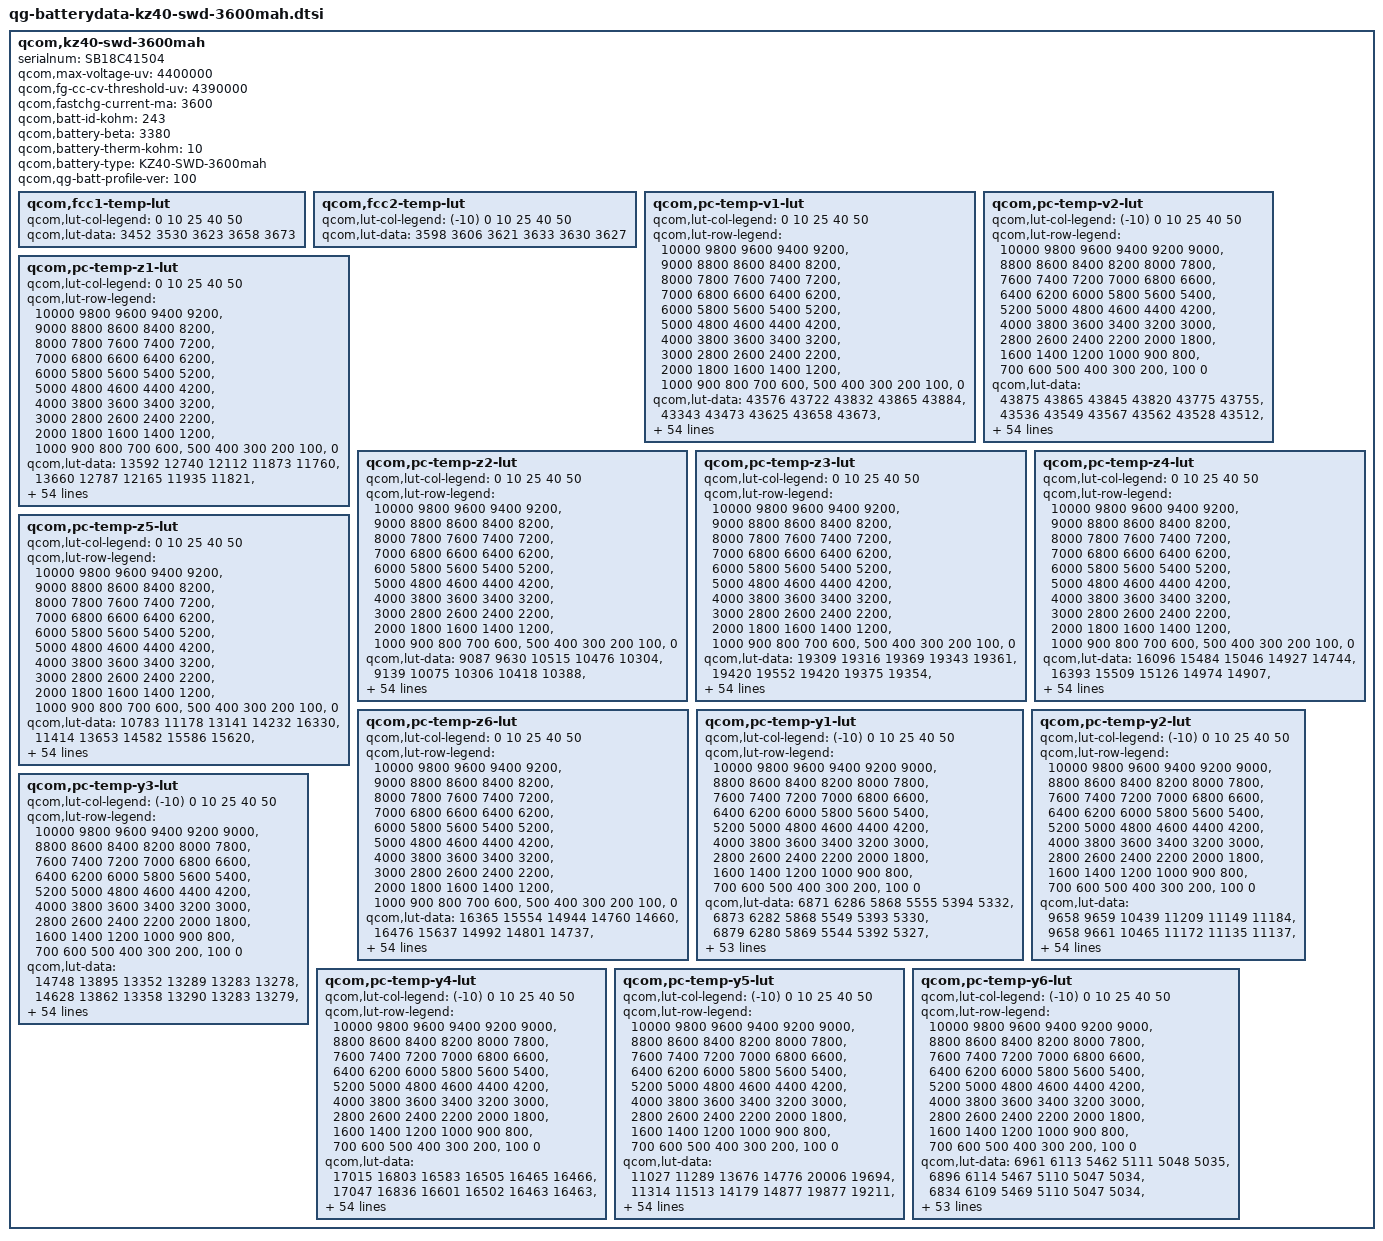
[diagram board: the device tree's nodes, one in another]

qcom,kz40-swd-3600mah {
    /* 3773938_Lenovo_KZ40_3600mAh_averaged_MasterSlave_Nov29th2018 */
    serialnum = "SB18C41504";
    qcom,max-voltage-uv = <4400000>;
    qcom,fg-cc-cv-threshold-uv = <4390000>;
    qcom,fastchg-current-ma = <3600>;
    qcom,batt-id-kohm = <243>;
    qcom,battery-beta = <3380>;
    qcom,battery-therm-kohm = <10>;
    qcom,battery-type = "KZ40-SWD-3600mah";
    qcom,qg-batt-profile-ver = <100>;

	qcom,fcc1-temp-lut {
		qcom,lut-col-legend = <0 10 25 40 50>;
		qcom,lut-data = <3452 3530 3623 3658 3673>;
	};

	qcom,fcc2-temp-lut {
		qcom,lut-col-legend = <(-10) 0 10 25 40 50>;
		qcom,lut-data = <3598 3606 3621 3633 3630 3627>;
	};

	qcom,pc-temp-v1-lut {
		qcom,lut-col-legend = <0 10 25 40 50>;
		qcom,lut-row-legend = <10000 9800 9600 9400 9200>,
			<9000 8800 8600 8400 8200>,
			<8000 7800 7600 7400 7200>,
			<7000 6800 6600 6400 6200>,
			<6000 5800 5600 5400 5200>,
			<5000 4800 4600 4400 4200>,
			<4000 3800 3600 3400 3200>,
			<3000 2800 2600 2400 2200>,
			<2000 1800 1600 1400 1200>,
			<1000 900 800 700 600>,
			<500 400 300 200 100>,
			<0>;
		qcom,lut-data = <43576 43722 43832 43865 43884>,
			<43343 43473 43625 43658 43673>,
			<43080 43230 43397 43442 43461>,
			<42820 42994 43164 43221 43244>,
			<42585 42761 42928 42992 43021>,
			<42361 42527 42689 42757 42788>,
			<42144 42296 42456 42523 42555>,
			<41931 42073 42224 42289 42322>,
			<41725 41857 41995 42058 42090>,
			<41527 41648 41768 41829 41861>,
			<41337 41445 41545 41602 41635>,
			<41143 41250 41329 41380 41413>,
			<40940 41052 41119 41159 41192>,
			<40730 40857 40915 40946 40976>,
			<40498 40655 40715 40741 40768>,
			<40226 40424 40518 40545 40566>,
			<39990 40165 40315 40354 40373>,
			<39835 39960 40112 40170 40189>,
			<39712 39828 39934 39993 40011>,
			<39588 39714 39794 39832 39846>,
			<39458 39581 39644 39671 39685>,
			<39330 39433 39414 39464 39490>,
			<39205 39268 39126 39185 39229>,
			<39083 39050 38922 38960 38999>,
			<38965 38821 38793 38828 38855>,
			<38851 38669 38688 38723 38740>,
			<38742 38562 38596 38618 38627>,
			<38641 38480 38516 38515 38518>,
			<38546 38416 38438 38421 38419>,
			<38463 38365 38361 38335 38329>,
			<38394 38320 38291 38259 38247>,
			<38335 38278 38228 38189 38173>,
			<38293 38240 38173 38128 38106>,
			<38267 38207 38123 38069 38043>,
			<38244 38178 38079 38017 37986>,
			<38210 38144 38037 37966 37930>,
			<38168 38110 37995 37916 37869>,
			<38117 38068 37953 37867 37807>,
			<38057 38004 37893 37803 37733>,
			<37983 37912 37802 37711 37640>,
			<37891 37809 37695 37603 37533>,
			<37766 37690 37578 37483 37413>,
			<37626 37556 37444 37347 37277>,
			<37469 37403 37282 37187 37118>,
			<37324 37261 37145 37053 36988>,
			<37225 37170 37061 36975 36918>,
			<37191 37138 37039 36956 36896>,
			<37166 37114 37027 36941 36881>,
			<37142 37090 37007 36921 36862>,
			<37084 37036 36947 36845 36768>,
			<36838 36773 36670 36543 36449>,
			<36382 36319 36224 36089 35991>,
			<35798 35734 35641 35499 35399>,
			<35004 34932 34841 34688 34585>,
			<33739 33667 33590 33417 33304>,
			<30000 30000 30000 30000 30000>;
	};

	qcom,pc-temp-v2-lut {
		qcom,lut-col-legend = <(-10) 0 10 25 40 50>;
		qcom,lut-row-legend = <10000 9800 9600 9400 9200 9000>,
			<8800 8600 8400 8200 8000 7800>,
			<7600 7400 7200 7000 6800 6600>,
			<6400 6200 6000 5800 5600 5400>,
			<5200 5000 4800 4600 4400 4200>,
			<4000 3800 3600 3400 3200 3000>,
			<2800 2600 2400 2200 2000 1800>,
			<1600 1400 1200 1000 900 800>,
			<700 600 500 400 300 200>,
			<100 0>;
		qcom,lut-data = <43875 43865 43845 43820 43775 43755>,
			<43536 43549 43567 43562 43528 43512>,
			<43215 43247 43300 43310 43285 43273>,
			<42910 42961 43044 43067 43046 43037>,
			<42621 42689 42798 42833 42813 42805>,
			<42349 42427 42557 42600 42580 42573>,
			<42095 42173 42315 42367 42347 42340>,
			<41854 41927 42076 42135 42114 42108>,
			<41614 41686 41845 41906 41885 41880>,
			<41368 41446 41620 41680 41658 41655>,
			<41165 41232 41400 41455 41434 41432>,
			<41038 41067 41184 41231 41214 41213>,
			<40925 40912 40974 41014 40998 40997>,
			<40694 40711 40783 40818 40790 40788>,
			<40230 40456 40608 40640 40586 40584>,
			<39830 40188 40411 40446 40390 40387>,
			<39619 39906 40155 40207 40199 40199>,
			<39455 39629 39885 39971 40015 40018>,
			<39287 39410 39666 39802 39842 39845>,
			<39120 39231 39478 39670 39679 39681>,
			<38962 39064 39293 39506 39494 39496>,
			<38808 38896 39096 39257 39253 39255>,
			<38663 38738 38908 39002 39012 39012>,
			<38538 38595 38746 38821 38832 38832>,
			<38426 38462 38602 38673 38681 38683>,
			<38329 38349 38475 38546 38553 38554>,
			<38246 38257 38364 38434 38442 38443>,
			<38172 38178 38264 38335 38342 38344>,
			<38104 38110 38171 38243 38250 38250>,
			<38040 38050 38082 38159 38164 38162>,
			<37982 37997 38009 38082 38086 38084>,
			<37927 37947 37947 38008 38017 38014>,
			<37875 37900 37894 37939 37951 37947>,
			<37820 37854 37841 37878 37884 37876>,
			<37764 37809 37791 37821 37816 37800>,
			<37705 37762 37742 37760 37737 37712>,
			<37644 37711 37695 37695 37641 37600>,
			<37581 37655 37645 37625 37541 37488>,
			<37514 37591 37584 37550 37457 37397>,
			<37445 37520 37513 37470 37378 37316>,
			<37375 37438 37429 37383 37290 37227>,
			<37305 37335 37322 37285 37191 37126>,
			<37232 37222 37204 37165 37074 37008>,
			<37156 37103 37079 37022 36935 36868>,
			<37073 36996 36964 36913 36838 36781>,
			<36972 36910 36887 36875 36812 36757>,
			<36912 36872 36854 36864 36798 36747>,
			<36852 36826 36814 36842 36779 36730>,
			<36766 36767 36760 36805 36741 36683>,
			<36637 36662 36647 36683 36574 36487>,
			<36408 36426 36369 36317 36188 36090>,
			<36027 35969 35888 35801 35652 35551>,
			<35446 35322 35226 35112 34949 34837>,
			<34590 34390 34272 34142 33948 33847>,
			<33143 32941 32907 32689 32621 32440>,
			<30208 27623 27450 28102 27502 27416>;
	};

	qcom,pc-temp-z1-lut {
		qcom,lut-col-legend = <0 10 25 40 50>;
		qcom,lut-row-legend = <10000 9800 9600 9400 9200>,
			<9000 8800 8600 8400 8200>,
			<8000 7800 7600 7400 7200>,
			<7000 6800 6600 6400 6200>,
			<6000 5800 5600 5400 5200>,
			<5000 4800 4600 4400 4200>,
			<4000 3800 3600 3400 3200>,
			<3000 2800 2600 2400 2200>,
			<2000 1800 1600 1400 1200>,
			<1000 900 800 700 600>,
			<500 400 300 200 100>,
			<0>;
		qcom,lut-data = <13592 12740 12112 11873 11760>,
			<13660 12787 12165 11935 11821>,
			<13669 12808 12188 11936 11824>,
			<13675 12818 12195 11936 11825>,
			<13672 12821 12187 11932 11824>,
			<13659 12811 12176 11923 11818>,
			<13653 12793 12171 11917 11815>,
			<13655 12782 12168 11913 11816>,
			<13656 12776 12166 11910 11817>,
			<13648 12773 12166 11908 11816>,
			<13623 12778 12166 11906 11815>,
			<13601 12792 12170 11905 11814>,
			<13560 12798 12177 11905 11814>,
			<13503 12780 12179 11905 11815>,
			<13469 12756 12167 11905 11815>,
			<13443 12741 12154 11904 11816>,
			<13423 12726 12152 11905 11817>,
			<13407 12720 12152 11907 11820>,
			<13391 12733 12155 11911 11822>,
			<13389 12752 12165 11913 11825>,
			<13408 12763 12176 11915 11827>,
			<13433 12769 12178 11917 11828>,
			<13446 12775 12179 11919 11829>,
			<13458 12782 12180 11921 11831>,
			<13465 12790 12179 11924 11834>,
			<13469 12792 12179 11928 11838>,
			<13472 12786 12183 11932 11843>,
			<13472 12782 12190 11937 11848>,
			<13469 12790 12196 11942 11853>,
			<13468 12805 12200 11947 11857>,
			<13477 12812 12203 11953 11861>,
			<13494 12818 12206 11958 11866>,
			<13508 12824 12208 11962 11871>,
			<13516 12825 12211 11966 11877>,
			<13523 12823 12223 11971 11883>,
			<13531 12826 12232 11977 11888>,
			<13541 12840 12234 11981 11893>,
			<13550 12855 12235 11986 11898>,
			<13556 12866 12238 11990 11902>,
			<13562 12876 12246 11995 11907>,
			<13576 12881 12255 12001 11912>,
			<13612 12883 12261 12006 11917>,
			<13631 12886 12265 12012 11921>,
			<13636 12893 12265 12018 11925>,
			<13650 12915 12271 12024 11929>,
			<13664 12898 12274 12027 11932>,
			<13646 12903 12277 12027 11935>,
			<13656 12916 12270 12028 11936>,
			<13640 12909 12282 12035 11939>,
			<13671 12904 12284 12039 11945>,
			<13661 12913 12287 12046 11953>,
			<13716 12950 12301 12055 11963>,
			<13745 12982 12320 12068 11977>,
			<13767 13040 12353 12086 11993>,
			<13767 13040 12353 12086 11993>,
			<13767 13040 12353 12086 11993>;
	};

	qcom,pc-temp-z2-lut {
		qcom,lut-col-legend = <0 10 25 40 50>;
		qcom,lut-row-legend = <10000 9800 9600 9400 9200>,
			<9000 8800 8600 8400 8200>,
			<8000 7800 7600 7400 7200>,
			<7000 6800 6600 6400 6200>,
			<6000 5800 5600 5400 5200>,
			<5000 4800 4600 4400 4200>,
			<4000 3800 3600 3400 3200>,
			<3000 2800 2600 2400 2200>,
			<2000 1800 1600 1400 1200>,
			<1000 900 800 700 600>,
			<500 400 300 200 100>,
			<0>;
		qcom,lut-data = <9087 9630 10515 10476 10304>,
			<9139 10075 10306 10418 10388>,
			<9625 10181 10387 10465 10427>,
			<10015 10160 10425 10501 10471>,
			<10065 10132 10394 10491 10470>,
			<10090 10106 10348 10447 10426>,
			<10101 10079 10314 10406 10386>,
			<10107 10059 10281 10360 10366>,
			<10111 10042 10270 10328 10347>,
			<10110 10031 10271 10329 10304>,
			<10105 10028 10274 10338 10220>,
			<10098 10027 10279 10347 10185>,
			<10079 10027 10289 10364 10201>,
			<10050 10051 10303 10375 10222>,
			<10018 10079 10325 10339 10234>,
			<9975 10085 10344 10266 10245>,
			<9949 10087 10345 10249 10250>,
			<9960 10091 10343 10268 10256>,
			<9984 10129 10344 10285 10266>,
			<9993 10176 10359 10294 10283>,
			<9980 10181 10372 10303 10306>,
			<9962 10170 10365 10300 10311>,
			<9951 10160 10340 10276 10298>,
			<9942 10154 10313 10261 10289>,
			<9938 10150 10278 10279 10320>,
			<9939 10150 10255 10321 10380>,
			<9941 10154 10282 10383 10403>,
			<9945 10159 10346 10491 10413>,
			<9951 10160 10373 10539 10417>,
			<9959 10161 10380 10455 10335>,
			<9972 10163 10383 10347 10212>,
			<9987 10167 10375 10320 10176>,
			<9984 10171 10359 10309 10161>,
			<9809 10176 10355 10307 10157>,
			<9613 10184 10363 10331 10188>,
			<9605 10193 10375 10365 10240>,
			<9674 10205 10394 10387 10294>,
			<9756 10217 10422 10406 10354>,
			<9860 10227 10448 10434 10383>,
			<9961 10235 10475 10490 10393>,
			<9971 10238 10493 10539 10399>,
			<9882 10197 10500 10553 10404>,
			<9806 10168 10505 10559 10408>,
			<9755 10102 10510 10562 10425>,
			<9659 10785 10550 10544 10429>,
			<9620 13816 10593 10471 10426>,
			<9615 12140 10576 10504 10423>,
			<9613 11889 10602 10493 10437>,
			<9600 12772 10603 10515 10514>,
			<9558 12818 10650 10633 10521>,
			<9456 12360 10815 10505 10290>,
			<9414 10860 10770 10392 10221>,
			<9363 10317 10762 10345 10172>,
			<9300 10057 10613 10265 10102>,
			<9300 10057 10613 10265 10102>,
			<9300 10057 10613 10265 10102>;
	};

	qcom,pc-temp-z3-lut {
		qcom,lut-col-legend = <0 10 25 40 50>;
		qcom,lut-row-legend = <10000 9800 9600 9400 9200>,
			<9000 8800 8600 8400 8200>,
			<8000 7800 7600 7400 7200>,
			<7000 6800 6600 6400 6200>,
			<6000 5800 5600 5400 5200>,
			<5000 4800 4600 4400 4200>,
			<4000 3800 3600 3400 3200>,
			<3000 2800 2600 2400 2200>,
			<2000 1800 1600 1400 1200>,
			<1000 900 800 700 600>,
			<500 400 300 200 100>,
			<0>;
		qcom,lut-data = <19309 19316 19369 19343 19361>,
			<19420 19552 19420 19375 19354>,
			<19699 19638 19458 19396 19372>,
			<19889 19663 19480 19409 19385>,
			<19879 19677 19492 19417 19395>,
			<19845 19685 19499 19423 19404>,
			<19814 19690 19498 19425 19408>,
			<19783 19691 19493 19424 19407>,
			<19757 19679 19488 19423 19405>,
			<19746 19666 19483 19418 19400>,
			<19738 19662 19478 19408 19389>,
			<19734 19660 19475 19401 19381>,
			<19732 19655 19473 19399 19379>,
			<19732 19622 19469 19396 19377>,
			<19744 19589 19455 19389 19374>,
			<19800 19588 19441 19379 19369>,
			<19844 19597 19439 19374 19365>,
			<19827 19602 19438 19372 19360>,
			<19786 19574 19437 19371 19356>,
			<19771 19539 19432 19369 19353>,
			<19779 19537 19428 19367 19351>,
			<19788 19553 19433 19368 19348>,
			<19791 19573 19446 19371 19346>,
			<19793 19594 19450 19374 19344>,
			<19795 19613 19439 19364 19341>,
			<19799 19617 19428 19350 19337>,
			<19803 19617 19424 19356 19343>,
			<19804 19617 19422 19388 19383>,
			<19804 19614 19423 19408 19408>,
			<19803 19608 19437 19412 19404>,
			<19799 19602 19451 19414 19397>,
			<19787 19595 19455 19412 19390>,
			<19756 19586 19458 19404 19384>,
			<19537 19577 19458 19397 19377>,
			<19300 19566 19453 19391 19368>,
			<19269 19559 19447 19385 19361>,
			<19267 19553 19443 19380 19358>,
			<19266 19548 19439 19375 19357>,
			<19264 19547 19434 19372 19356>,
			<19263 19548 19430 19370 19355>,
			<19262 19543 19427 19369 19355>,
			<19263 19459 19423 19370 19357>,
			<19264 19398 19419 19372 19360>,
			<19264 19287 19416 19372 19363>,
			<19265 19260 19405 19368 19361>,
			<19266 19257 19395 19357 19340>,
			<19266 19258 19393 19348 19339>,
			<19266 19258 19361 19346 19335>,
			<19266 19258 19358 19344 19323>,
			<19267 19257 19350 19337 19332>,
			<19270 19258 19335 19354 19360>,
			<19272 19259 19340 19367 19366>,
			<19275 19261 19332 19369 19366>,
			<19279 19262 19340 19372 19369>,
			<19279 19262 19340 19372 19369>,
			<19279 19262 19340 19372 19369>;
	};

	qcom,pc-temp-z4-lut {
		qcom,lut-col-legend = <0 10 25 40 50>;
		qcom,lut-row-legend = <10000 9800 9600 9400 9200>,
			<9000 8800 8600 8400 8200>,
			<8000 7800 7600 7400 7200>,
			<7000 6800 6600 6400 6200>,
			<6000 5800 5600 5400 5200>,
			<5000 4800 4600 4400 4200>,
			<4000 3800 3600 3400 3200>,
			<3000 2800 2600 2400 2200>,
			<2000 1800 1600 1400 1200>,
			<1000 900 800 700 600>,
			<500 400 300 200 100>,
			<0>;
		qcom,lut-data = <16096 15484 15046 14927 14744>,
			<16393 15509 15126 14974 14907>,
			<16209 15494 15080 14951 14897>,
			<16001 15355 15027 14913 14872>,
			<15859 15195 14966 14879 14847>,
			<15732 15099 14905 14844 14820>,
			<15628 15020 14863 14814 14793>,
			<15545 14961 14830 14787 14766>,
			<15472 14918 14801 14766 14745>,
			<15404 14882 14774 14753 14739>,
			<15342 14848 14753 14744 14738>,
			<15282 14816 14742 14735 14735>,
			<15222 14797 14735 14725 14727>,
			<15163 14786 14728 14717 14717>,
			<15098 14779 14719 14713 14709>,
			<15021 14772 14711 14709 14702>,
			<14961 14765 14707 14704 14696>,
			<14932 14763 14703 14695 14690>,
			<14913 14764 14699 14688 14685>,
			<14892 14767 14689 14683 14682>,
			<14865 14762 14681 14680 14680>,
			<14841 14739 14721 14698 14690>,
			<14828 14724 14821 14798 14780>,
			<14819 14766 14861 14860 14850>,
			<14811 14830 14867 14859 14848>,
			<14804 14844 14870 14858 14841>,
			<14798 14841 14862 14844 14821>,
			<14795 14836 14837 14792 14761>,
			<14794 14822 14811 14748 14716>,
			<14793 14799 14779 14725 14705>,
			<14791 14781 14751 14708 14698>,
			<14790 14766 14730 14698 14691>,
			<14800 14753 14713 14690 14683>,
			<15019 14743 14704 14688 14681>,
			<15264 14734 14699 14688 14682>,
			<15290 14727 14696 14689 14684>,
			<15274 14719 14694 14690 14686>,
			<15256 14714 14693 14690 14688>,
			<15242 14712 14694 14693 14691>,
			<15228 14711 14705 14702 14698>,
			<15217 14714 14714 14709 14703>,
			<15210 14802 14709 14705 14699>,
			<15199 14861 14704 14696 14691>,
			<15179 14974 14707 14699 14695>,
			<15072 14956 14699 14696 14691>,
			<15049 14922 14674 14677 14677>,
			<15045 14916 14663 14669 14665>,
			<15039 14910 14682 14651 14647>,
			<15032 14902 14674 14636 14639>,
			<15018 14898 14686 14650 14638>,
			<15017 14909 14730 14667 14650>,
			<15041 14921 14733 14661 14651>,
			<15058 14930 14746 14662 14655>,
			<15084 14945 14744 14664 14656>,
			<15084 14945 14744 14664 14656>,
			<15084 14945 14744 14664 14656>;
	};

	qcom,pc-temp-z5-lut {
		qcom,lut-col-legend = <0 10 25 40 50>;
		qcom,lut-row-legend = <10000 9800 9600 9400 9200>,
			<9000 8800 8600 8400 8200>,
			<8000 7800 7600 7400 7200>,
			<7000 6800 6600 6400 6200>,
			<6000 5800 5600 5400 5200>,
			<5000 4800 4600 4400 4200>,
			<4000 3800 3600 3400 3200>,
			<3000 2800 2600 2400 2200>,
			<2000 1800 1600 1400 1200>,
			<1000 900 800 700 600>,
			<500 400 300 200 100>,
			<0>;
		qcom,lut-data = <10783 11178 13141 14232 16330>,
			<11414 13653 14582 15586 15620>,
			<12696 14856 15676 16442 16548>,
			<13536 15370 16568 17038 17277>,
			<13528 15805 17356 17563 17988>,
			<13478 16467 17975 18023 18655>,
			<13441 17168 18322 18490 19334>,
			<13408 17512 18543 19066 20255>,
			<13385 17618 18892 19476 21017>,
			<13410 17734 19718 19537 20803>,
			<13504 18404 20771 19561 19717>,
			<13576 19782 21857 19681 19226>,
			<13581 20300 23019 20430 19791>,
			<13581 19322 23372 21046 20561>,
			<13962 18231 22701 20684 21032>,
			<15989 18977 22017 19938 21477>,
			<17577 21831 22326 19854 21627>,
			<17319 23253 23429 20753 21985>,
			<16674 20898 24453 21915 22505>,
			<16476 17830 25449 23153 23219>,
			<17189 17956 26772 24387 24161>,
			<18276 21353 31110 24929 24218>,
			<19165 26244 38942 25157 22385>,
			<20034 36237 40876 24998 20005>,
			<21113 47491 32753 21338 17450>,
			<22748 49192 24107 16413 15002>,
			<24723 45553 21195 16066 15163>,
			<26599 41334 19354 17877 18813>,
			<28712 38134 19070 19990 22092>,
			<29989 35157 20634 22187 23474>,
			<29639 32880 23022 24502 24570>,
			<28340 31179 25970 26594 26138>,
			<26188 29635 29654 28578 28175>,
			<18925 27827 32609 30192 29030>,
			<11699 26020 35323 31788 28964>,
			<10843 25107 36838 32833 28868>,
			<10835 24998 36861 32314 28803>,
			<10831 25275 36671 30433 28661>,
			<10827 26221 36006 28403 28298>,
			<10824 28073 32928 25583 25745>,
			<10826 28635 29678 23624 23342>,
			<10847 23041 27859 23759 23624>,
			<10870 18664 26365 24075 24324>,
			<10894 12421 24692 23476 24004>,
			<11108 11308 24350 22229 23025>,
			<11119 11255 24789 21494 18954>,
			<11096 11233 25058 20063 19563>,
			<11080 11206 17373 21777 21393>,
			<11066 11213 17226 24579 20459>,
			<11120 11252 16405 19724 22731>,
			<11204 11345 14182 18581 23306>,
			<11151 11289 14002 20086 23312>,
			<11085 11230 13330 19686 21422>,
			<10979 11150 13465 19233 20372>,
			<10979 11150 13465 19233 20372>,
			<10979 11150 13465 19233 20372>;
	};

	qcom,pc-temp-z6-lut {
		qcom,lut-col-legend = <0 10 25 40 50>;
		qcom,lut-row-legend = <10000 9800 9600 9400 9200>,
			<9000 8800 8600 8400 8200>,
			<8000 7800 7600 7400 7200>,
			<7000 6800 6600 6400 6200>,
			<6000 5800 5600 5400 5200>,
			<5000 4800 4600 4400 4200>,
			<4000 3800 3600 3400 3200>,
			<3000 2800 2600 2400 2200>,
			<2000 1800 1600 1400 1200>,
			<1000 900 800 700 600>,
			<500 400 300 200 100>,
			<0>;
		qcom,lut-data = <16365 15554 14944 14760 14660>,
			<16476 15637 14992 14801 14737>,
			<16446 15642 14985 14798 14737>,
			<16397 15558 14974 14791 14737>,
			<16310 15460 14949 14782 14735>,
			<16178 15396 14916 14768 14726>,
			<16070 15341 14891 14754 14716>,
			<15986 15294 14869 14742 14706>,
			<15914 15253 14851 14731 14695>,
			<15856 15218 14833 14721 14688>,
			<15807 15191 14820 14711 14681>,
			<15757 15169 14814 14704 14675>,
			<15695 15144 14811 14698 14670>,
			<15636 15108 14805 14693 14665>,
			<15597 15078 14788 14686 14660>,
			<15572 15072 14773 14679 14655>,
			<15549 15071 14771 14674 14649>,
			<15518 15068 14770 14669 14644>,
			<15486 15059 14768 14666 14640>,
			<15474 15049 14763 14663 14637>,
			<15472 15048 14759 14661 14635>,
			<15471 15052 14780 14669 14639>,
			<15472 15058 14832 14715 14677>,
			<15474 15088 14849 14743 14706>,
			<15476 15129 14848 14740 14705>,
			<15478 15138 14846 14734 14701>,
			<15481 15139 14840 14729 14697>,
			<15484 15140 14831 14724 14693>,
			<15487 15135 14824 14720 14689>,
			<15490 15125 14820 14714 14683>,
			<15488 15117 14816 14708 14677>,
			<15485 15110 14812 14703 14671>,
			<15480 15104 14808 14697 14665>,
			<15469 15098 14805 14693 14661>,
			<15460 15093 14803 14690 14657>,
			<15458 15091 14801 14689 14654>,
			<15458 15091 14800 14687 14654>,
			<15458 15091 14800 14686 14655>,
			<15461 15094 14801 14686 14656>,
			<15465 15102 14806 14690 14659>,
			<15471 15107 14811 14694 14662>,
			<15479 15110 14810 14693 14662>,
			<15486 15112 14808 14692 14661>,
			<15493 15116 14811 14695 14664>,
			<15470 15108 14807 14692 14663>,
			<15464 15099 14795 14680 14648>,
			<15463 15098 14790 14672 14641>,
			<15461 15097 14783 14664 14632>,
			<15461 15097 14780 14657 14622>,
			<15466 15101 14784 14661 14627>,
			<15477 15114 14799 14680 14650>,
			<15501 15130 14808 14686 14656>,
			<15527 15147 14815 14692 14661>,
			<15568 15175 14828 14699 14667>,
			<15568 15175 14828 14699 14667>,
			<15568 15175 14828 14699 14667>;
	};

	qcom,pc-temp-y1-lut {
		qcom,lut-col-legend = <(-10) 0 10 25 40 50>;
		qcom,lut-row-legend = <10000 9800 9600 9400 9200 9000>,
			<8800 8600 8400 8200 8000 7800>,
			<7600 7400 7200 7000 6800 6600>,
			<6400 6200 6000 5800 5600 5400>,
			<5200 5000 4800 4600 4400 4200>,
			<4000 3800 3600 3400 3200 3000>,
			<2800 2600 2400 2200 2000 1800>,
			<1600 1400 1200 1000 900 800>,
			<700 600 500 400 300 200>,
			<100 0>;
		qcom,lut-data = <6871 6286 5868 5555 5394 5332>,
			<6873 6282 5868 5549 5393 5330>,
			<6879 6280 5869 5544 5392 5327>,
			<6886 6279 5870 5540 5390 5325>,
			<6892 6280 5871 5536 5389 5323>,
			<6896 6280 5873 5534 5387 5321>,
			<6908 6283 5878 5534 5385 5319>,
			<6924 6285 5884 5535 5381 5317>,
			<6925 6287 5887 5534 5378 5315>,
			<6912 6289 5889 5533 5375 5313>,
			<6904 6291 5889 5532 5373 5312>,
			<6903 6294 5885 5530 5373 5311>,
			<6902 6298 5880 5528 5372 5311>,
			<6902 6299 5879 5527 5371 5310>,
			<6905 6302 5881 5524 5369 5309>,
			<6906 6305 5883 5524 5369 5309>,
			<6912 6318 5891 5529 5370 5309>,
			<6922 6334 5900 5534 5371 5309>,
			<6922 6336 5901 5535 5371 5309>,
			<6913 6328 5902 5535 5370 5310>,
			<6907 6322 5902 5535 5370 5311>,
			<6913 6318 5902 5536 5371 5312>,
			<6922 6315 5901 5537 5373 5313>,
			<6923 6314 5899 5538 5375 5314>,
			<6922 6316 5896 5540 5377 5315>,
			<6922 6317 5894 5542 5379 5316>,
			<6929 6317 5897 5547 5380 5319>,
			<6942 6316 5901 5551 5382 5322>,
			<6940 6317 5902 5550 5384 5323>,
			<6919 6323 5903 5549 5388 5325>,
			<6905 6325 5903 5548 5391 5327>,
			<6906 6319 5900 5552 5394 5331>,
			<6907 6310 5897 5556 5396 5335>,
			<6911 6309 5898 5557 5399 5338>,
			<6922 6311 5903 5558 5401 5340>,
			<6929 6311 5905 5558 5403 5341>,
			<6925 6309 5904 5560 5406 5343>,
			<6917 6305 5903 5562 5408 5346>,
			<6908 6304 5902 5565 5409 5347>,
			<6895 6304 5901 5568 5410 5349>,
			<6888 6304 5900 5569 5412 5352>,
			<6893 6312 5903 5564 5414 5354>,
			<6905 6319 5906 5564 5417 5357>,
			<6928 6315 5908 5573 5419 5359>,
			<6926 6311 5910 5572 5427 5364>,
			<7000 6352 5923 5584 5431 5367>,
			<6960 6349 5922 5586 5430 5368>,
			<6973 6353 5926 5590 5431 5367>,
			<6979 6357 5932 5589 5431 5368>,
			<6979 6376 5937 5583 5432 5370>,
			<7006 6386 5940 5587 5439 5375>,
			<7041 6387 5952 5600 5447 5381>,
			<7040 6415 5973 5616 5455 5389>,
			<7059 6443 6004 5636 5468 5403>,
			<7059 6443 6004 5636 5468 5403>,
			<7059 6443 6004 5636 5468 5403>;
	};

	qcom,pc-temp-y2-lut {
		qcom,lut-col-legend = <(-10) 0 10 25 40 50>;
		qcom,lut-row-legend = <10000 9800 9600 9400 9200 9000>,
			<8800 8600 8400 8200 8000 7800>,
			<7600 7400 7200 7000 6800 6600>,
			<6400 6200 6000 5800 5600 5400>,
			<5200 5000 4800 4600 4400 4200>,
			<4000 3800 3600 3400 3200 3000>,
			<2800 2600 2400 2200 2000 1800>,
			<1600 1400 1200 1000 900 800>,
			<700 600 500 400 300 200>,
			<100 0>;
		qcom,lut-data = <9658 9659 10439 11209 11149 11184>,
			<9658 9661 10465 11172 11135 11137>,
			<9658 9662 10497 11137 11114 11093>,
			<9658 9664 10528 11104 11091 11052>,
			<9658 9665 10554 11074 11068 11015>,
			<9658 9666 10569 11046 11049 10982>,
			<9659 9668 10575 11021 11020 10954>,
			<9659 9669 10579 10998 10986 10930>,
			<9660 9671 10589 10979 10969 10910>,
			<9660 9675 10607 10962 10957 10893>,
			<9660 9677 10626 10955 10947 10877>,
			<9660 9678 10637 10963 10940 10855>,
			<9661 9678 10650 10974 10933 10835>,
			<9661 9679 10692 10978 10920 10837>,
			<9661 9680 10795 10980 10896 10859>,
			<9661 9681 10848 10984 10886 10884>,
			<9661 9678 10846 11032 10926 10915>,
			<9661 9674 10843 11104 11000 10955>,
			<9661 9672 10841 11166 11092 11025>,
			<9661 9672 10841 11227 11215 11138>,
			<9661 9671 10842 11247 11264 11186>,
			<9661 9671 10858 11199 11232 11162>,
			<9661 9671 10879 11146 11191 11131>,
			<9661 9671 10891 11151 11173 11119>,
			<9660 9671 10899 11181 11160 11111>,
			<9660 9670 10908 11204 11158 11108>,
			<9660 9670 10921 11224 11181 11117>,
			<9660 9669 10932 11243 11212 11134>,
			<9660 9668 10755 11262 11229 11164>,
			<9660 9667 10193 11284 11242 11213>,
			<9660 9666 9959 11291 11257 11242>,
			<9660 9665 10379 11288 11288 11255>,
			<9660 9665 10840 11285 11318 11263>,
			<9660 9664 10756 11289 11340 11258>,
			<9659 9663 10363 11297 11369 11242>,
			<9659 9662 10087 11298 11372 11226>,
			<9659 9662 9916 11278 11305 11185>,
			<9659 9661 9792 11252 11241 11151>,
			<9659 9660 9747 11226 11230 11152>,
			<9659 9660 9719 11200 11226 11158>,
			<9659 9659 9704 11196 11221 11157>,
			<9658 9659 9695 11216 11214 11118>,
			<9658 9658 9689 11213 11213 11106>,
			<9658 9658 9684 11151 11225 11133>,
			<9658 9657 9677 11089 11160 10993>,
			<9658 9657 9676 11060 11091 10915>,
			<9658 9657 9673 11057 11076 10907>,
			<9658 9657 9671 11067 11075 10941>,
			<9657 9657 9669 11062 11083 10941>,
			<9657 9656 9669 11049 11074 10882>,
			<9657 9656 9667 10960 11022 10855>,
			<9657 9656 9664 10917 10935 10791>,
			<9656 9655 9661 10833 10876 10715>,
			<9656 9655 9659 10714 10745 10553>,
			<9656 9655 9659 10714 10745 10553>,
			<9656 9655 9659 10714 10745 10553>;
	};

	qcom,pc-temp-y3-lut {
		qcom,lut-col-legend = <(-10) 0 10 25 40 50>;
		qcom,lut-row-legend = <10000 9800 9600 9400 9200 9000>,
			<8800 8600 8400 8200 8000 7800>,
			<7600 7400 7200 7000 6800 6600>,
			<6400 6200 6000 5800 5600 5400>,
			<5200 5000 4800 4600 4400 4200>,
			<4000 3800 3600 3400 3200 3000>,
			<2800 2600 2400 2200 2000 1800>,
			<1600 1400 1200 1000 900 800>,
			<700 600 500 400 300 200>,
			<100 0>;
		qcom,lut-data = <14748 13895 13352 13289 13283 13278>,
			<14628 13862 13358 13290 13283 13279>,
			<14513 13830 13366 13292 13284 13279>,
			<14406 13799 13373 13296 13285 13280>,
			<14310 13769 13380 13299 13286 13280>,
			<14225 13742 13384 13302 13286 13280>,
			<14156 13716 13386 13304 13287 13281>,
			<14093 13691 13387 13307 13287 13281>,
			<14025 13667 13387 13308 13288 13282>,
			<13950 13645 13387 13308 13289 13284>,
			<13898 13620 13386 13308 13290 13287>,
			<13878 13582 13386 13308 13290 13288>,
			<13863 13546 13385 13309 13291 13288>,
			<13835 13543 13383 13310 13291 13289>,
			<13785 13559 13376 13314 13290 13289>,
			<13751 13568 13371 13316 13290 13289>,
			<13743 13538 13369 13312 13292 13291>,
			<13738 13490 13367 13309 13294 13294>,
			<13736 13468 13363 13309 13295 13294>,
			<13734 13457 13358 13311 13296 13294>,
			<13733 13449 13353 13312 13296 13293>,
			<13731 13441 13348 13308 13292 13288>,
			<13729 13434 13344 13302 13288 13281>,
			<13729 13431 13339 13298 13285 13279>,
			<13735 13428 13334 13295 13284 13279>,
			<13742 13427 13331 13294 13283 13278>,
			<13754 13428 13330 13294 13283 13279>,
			<13769 13432 13329 13294 13283 13280>,
			<13785 13439 13316 13295 13283 13279>,
			<13802 13457 13280 13296 13281 13278>,
			<13822 13476 13265 13297 13281 13277>,
			<13848 13495 13293 13297 13282 13278>,
			<13878 13515 13324 13296 13283 13279>,
			<13907 13537 13324 13297 13284 13280>,
			<13936 13561 13317 13298 13285 13280>,
			<13968 13589 13314 13298 13286 13280>,
			<14002 13621 13321 13298 13284 13280>,
			<14040 13658 13330 13297 13282 13279>,
			<14082 13700 13336 13295 13282 13279>,
			<14131 13748 13342 13293 13282 13280>,
			<14183 13798 13344 13292 13283 13281>,
			<14240 13850 13342 13295 13283 13282>,
			<14300 13906 13343 13295 13284 13281>,
			<14365 13974 13366 13292 13282 13278>,
			<14443 14052 13398 13294 13281 13279>,
			<14421 14065 13411 13293 13286 13285>,
			<14479 14118 13433 13301 13289 13290>,
			<14551 14172 13456 13304 13294 13293>,
			<14618 14230 13483 13313 13298 13293>,
			<14699 14282 13509 13313 13295 13289>,
			<14781 14336 13530 13305 13292 13288>,
			<14873 14417 13573 13312 13294 13290>,
			<15001 14567 13671 13318 13298 13294>,
			<15176 14718 13812 13328 13303 13298>,
			<15176 14718 13812 13328 13303 13298>,
			<15176 14718 13812 13328 13303 13298>;
	};

	qcom,pc-temp-y4-lut {
		qcom,lut-col-legend = <(-10) 0 10 25 40 50>;
		qcom,lut-row-legend = <10000 9800 9600 9400 9200 9000>,
			<8800 8600 8400 8200 8000 7800>,
			<7600 7400 7200 7000 6800 6600>,
			<6400 6200 6000 5800 5600 5400>,
			<5200 5000 4800 4600 4400 4200>,
			<4000 3800 3600 3400 3200 3000>,
			<2800 2600 2400 2200 2000 1800>,
			<1600 1400 1200 1000 900 800>,
			<700 600 500 400 300 200>,
			<100 0>;
		qcom,lut-data = <17015 16803 16583 16505 16465 16466>,
			<17047 16836 16601 16502 16463 16463>,
			<17106 16898 16632 16499 16462 16460>,
			<17170 16968 16665 16498 16462 16459>,
			<17223 17027 16693 16497 16462 16459>,
			<17245 17053 16706 16497 16463 16459>,
			<17242 17056 16708 16497 16464 16461>,
			<17237 17057 16709 16499 16467 16464>,
			<17242 17057 16713 16501 16470 16465>,
			<17275 17057 16724 16508 16474 16466>,
			<17322 17058 16737 16516 16479 16467>,
			<17401 17152 16749 16524 16484 16471>,
			<17485 17289 16766 16534 16490 16476>,
			<17446 17288 16809 16549 16498 16481>,
			<17161 17159 16906 16571 16510 16489>,
			<16970 17032 16954 16592 16522 16496>,
			<16963 16948 16890 16608 16533 16503>,
			<16958 16882 16795 16625 16544 16511>,
			<16947 16851 16752 16653 16567 16529>,
			<16924 16835 16730 16691 16601 16560>,
			<16899 16817 16701 16702 16614 16573>,
			<16876 16787 16648 16620 16567 16539>,
			<16856 16754 16595 16523 16506 16495>,
			<16844 16729 16572 16496 16482 16476>,
			<16836 16707 16558 16482 16466 16464>,
			<16831 16697 16549 16479 16461 16461>,
			<16827 16702 16543 16481 16464 16463>,
			<16824 16710 16540 16485 16470 16466>,
			<16823 16710 16560 16490 16477 16472>,
			<16824 16704 16626 16495 16488 16483>,
			<16824 16701 16653 16502 16499 16494>,
			<16823 16700 16599 16509 16513 16508>,
			<16822 16701 16539 16517 16523 16517>,
			<16823 16704 16543 16523 16525 16519>,
			<16826 16709 16575 16529 16525 16521>,
			<16830 16715 16598 16529 16523 16519>,
			<16831 16720 16612 16520 16499 16495>,
			<16833 16725 16622 16509 16476 16472>,
			<16835 16728 16631 16502 16475 16471>,
			<16841 16731 16638 16496 16474 16471>,
			<16850 16732 16644 16495 16475 16471>,
			<16864 16725 16650 16496 16476 16472>,
			<16885 16719 16651 16496 16475 16471>,
			<16920 16716 16648 16493 16463 16458>,
			<16946 16726 16653 16481 16457 16450>,
			<16892 16722 16652 16497 16470 16468>,
			<16908 16738 16677 16508 16486 16493>,
			<16927 16772 16719 16531 16516 16530>,
			<16950 16820 16774 16567 16557 16562>,
			<16967 16868 16801 16583 16523 16506>,
			<16957 16864 16785 16525 16472 16468>,
			<16933 16815 16769 16527 16474 16469>,
			<16929 16811 16781 16549 16491 16479>,
			<16951 16832 16825 16612 16555 16560>,
			<16951 16832 16825 16612 16555 16560>,
			<16951 16832 16825 16612 16555 16560>;
	};

	qcom,pc-temp-y5-lut {
		qcom,lut-col-legend = <(-10) 0 10 25 40 50>;
		qcom,lut-row-legend = <10000 9800 9600 9400 9200 9000>,
			<8800 8600 8400 8200 8000 7800>,
			<7600 7400 7200 7000 6800 6600>,
			<6400 6200 6000 5800 5600 5400>,
			<5200 5000 4800 4600 4400 4200>,
			<4000 3800 3600 3400 3200 3000>,
			<2800 2600 2400 2200 2000 1800>,
			<1600 1400 1200 1000 900 800>,
			<700 600 500 400 300 200>,
			<100 0>;
		qcom,lut-data = <11027 11289 13676 14776 20006 19694>,
			<11314 11513 14179 14877 19877 19211>,
			<11590 11794 14866 15510 19521 18671>,
			<11847 12079 15581 16353 19072 18095>,
			<12079 12313 16172 17082 18662 17507>,
			<12277 12444 16485 17375 18424 16927>,
			<12475 12497 16600 17545 17880 16189>,
			<12631 12525 16666 17695 17077 15555>,
			<12578 12524 16626 17351 16607 15637>,
			<12170 12507 16354 16514 16141 16375>,
			<11908 12526 15985 15732 15687 16786>,
			<13448 12649 15266 15083 15282 16494>,
			<15838 12910 14532 14572 14870 15957>,
			<15939 14003 14580 14380 14328 15415>,
			<14035 17724 15341 14278 13639 14773>,
			<12737 19919 16339 14164 13350 14503>,
			<12641 17440 17946 13916 13399 14607>,
			<12592 13814 19538 13692 13501 14736>,
			<12600 13163 20005 14183 13677 14714>,
			<12678 13163 20190 16087 14084 14588>,
			<12729 13151 20357 17925 14783 14564>,
			<12532 13078 20585 19744 17514 15873>,
			<12180 12951 20756 21024 20237 17417>,
			<11970 12753 20323 20588 20375 17641>,
			<11789 12398 18774 19047 20015 17676>,
			<11701 12056 18042 18216 19579 17665>,
			<11720 11744 18222 17934 18873 17621>,
			<11750 11502 18430 17782 18022 17536>,
			<11756 11511 17206 18170 17163 16969>,
			<11752 11701 13256 19186 16277 15614>,
			<11750 11810 11597 19573 16017 15099>,
			<11873 11872 14138 19470 16395 15370>,
			<12063 11983 16930 19377 17041 15835>,
			<12095 12078 16367 19845 18101 16469>,
			<12067 12209 14036 20861 19571 17355>,
			<12041 12344 13072 21209 19994 18014>,
			<12030 12466 13091 21087 19531 18519>,
			<12021 12590 13126 20826 18968 18848>,
			<11995 12741 13203 19725 18610 18935>,
			<11931 12927 13338 17850 18286 18949>,
			<11893 13009 13357 17459 18088 18864>,
			<11919 12906 12898 18286 17976 18564>,
			<11958 12720 12680 18143 18049 18149>,
			<12021 12429 12730 16283 18476 17456>,
			<12200 12198 12654 17132 16630 16781>,
			<12357 12311 12953 15206 16471 16787>,
			<12375 12576 13084 16746 16221 17335>,
			<12787 12662 13084 16432 16622 16764>,
			<12880 12930 13248 17451 16707 15858>,
			<13123 13050 13790 17555 16558 16006>,
			<13079 13233 13583 16760 19345 18161>,
			<12740 12751 13204 19290 19674 19272>,
			<12236 12512 13119 19832 21909 20256>,
			<12091 12408 12830 20416 22331 22585>,
			<12091 12408 12830 20416 22331 22585>,
			<12091 12408 12830 20416 22331 22585>;
	};

	qcom,pc-temp-y6-lut {
		qcom,lut-col-legend = <(-10) 0 10 25 40 50>;
		qcom,lut-row-legend = <10000 9800 9600 9400 9200 9000>,
			<8800 8600 8400 8200 8000 7800>,
			<7600 7400 7200 7000 6800 6600>,
			<6400 6200 6000 5800 5600 5400>,
			<5200 5000 4800 4600 4400 4200>,
			<4000 3800 3600 3400 3200 3000>,
			<2800 2600 2400 2200 2000 1800>,
			<1600 1400 1200 1000 900 800>,
			<700 600 500 400 300 200>,
			<100 0>;
		qcom,lut-data = <6961 6113 5462 5111 5048 5035>,
			<6896 6114 5467 5110 5047 5034>,
			<6834 6109 5469 5110 5047 5034>,
			<6773 6098 5468 5110 5047 5034>,
			<6716 6084 5466 5110 5048 5034>,
			<6661 6066 5463 5110 5048 5034>,
			<6609 6043 5456 5110 5049 5034>,
			<6560 6016 5445 5110 5049 5035>,
			<6512 5990 5438 5111 5050 5036>,
			<6461 5961 5432 5111 5052 5038>,
			<6437 5947 5427 5112 5053 5040>,
			<6439 5947 5422 5114 5055 5042>,
			<6444 5948 5419 5116 5057 5043>,
			<6424 5943 5422 5120 5059 5045>,
			<6312 5915 5437 5128 5062 5047>,
			<6234 5882 5446 5134 5065 5050>,
			<6226 5844 5429 5137 5069 5053>,
			<6221 5806 5403 5141 5074 5057>,
			<6215 5787 5388 5148 5082 5063>,
			<6208 5777 5377 5160 5091 5072>,
			<6201 5767 5365 5164 5095 5075>,
			<6194 5756 5346 5137 5079 5061>,
			<6187 5747 5328 5105 5058 5043>,
			<6186 5742 5320 5095 5049 5036>,
			<6188 5739 5314 5090 5044 5032>,
			<6192 5738 5313 5088 5042 5031>,
			<6198 5744 5314 5090 5043 5032>,
			<6209 5755 5317 5092 5045 5034>,
			<6220 5766 5319 5094 5047 5036>,
			<6232 5780 5322 5098 5050 5038>,
			<6247 5796 5326 5101 5053 5041>,
			<6265 5813 5333 5104 5058 5046>,
			<6286 5831 5342 5108 5062 5050>,
			<6307 5853 5351 5111 5064 5051>,
			<6330 5877 5361 5115 5065 5052>,
			<6355 5903 5372 5116 5065 5052>,
			<6383 5932 5386 5114 5057 5044>,
			<6413 5964 5403 5112 5050 5038>,
			<6446 5999 5421 5110 5050 5038>,
			<6483 6037 5442 5108 5050 5039>,
			<6525 6078 5464 5108 5051 5040>,
			<6571 6117 5487 5113 5053 5041>,
			<6623 6161 5515 5114 5052 5040>,
			<6684 6214 5551 5115 5049 5034>,
			<6757 6282 5599 5116 5047 5035>,
			<6746 6293 5612 5123 5056 5044>,
			<6795 6340 5644 5134 5063 5055>,
			<6858 6392 5680 5144 5075 5068>,
			<6915 6452 5722 5162 5090 5077>,
			<6984 6507 5758 5168 5078 5058>,
			<7050 6551 5779 5148 5062 5048>,
			<7126 6600 5824 5159 5065 5050>,
			<7235 6720 5929 5177 5075 5057>,
			<7393 6856 6068 5213 5099 5085>,
			<7393 6856 6068 5213 5099 5085>,
			<7393 6856 6068 5213 5099 5085>;
	};

};
